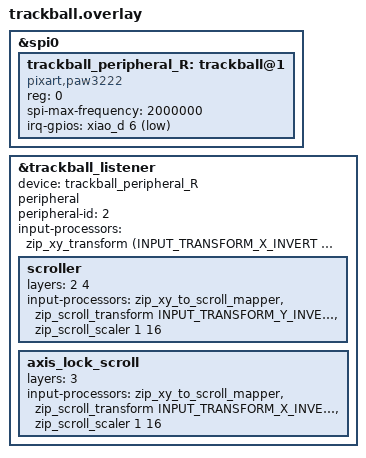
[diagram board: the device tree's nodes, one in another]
&spi0 {
    status = "okay";

    trackball_peripheral_R: trackball@1 {
        status = "okay";
        compatible = "pixart,paw3222";
        reg = <0>;
        spi-max-frequency = <2000000>;
        irq-gpios = <&xiao_d 6 (GPIO_ACTIVE_LOW | GPIO_PULL_UP)>;
        //cpi setting
        // res-cpi = <800>;
    };
};


&trackball_listener {
    status = "okay";
    device = <&trackball_peripheral_R>;
    peripheral;
    peripheral-id = <2>;

    input-processors =
        <&zip_xy_transform (INPUT_TRANSFORM_X_INVERT | INPUT_TRANSFORM_Y_INVERT)>;

    scroller {
        layers = <2 4>;
        input-processors =
            <&zip_xy_to_scroll_mapper>,
            <&zip_scroll_transform INPUT_TRANSFORM_Y_INVERT>,
            <&zip_scroll_scaler 1 16>;
    };

    axis_lock_scroll {
        layers = <3>;
        input-processors =
            <&zip_xy_to_scroll_mapper>,
            <&zip_scroll_transform INPUT_TRANSFORM_X_INVERT>,
            <&zip_scroll_scaler 1 16>;
    };
};
